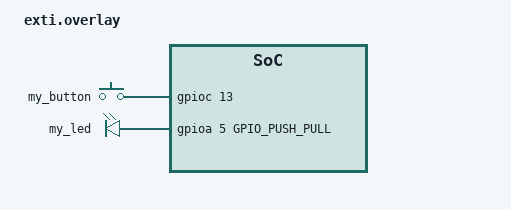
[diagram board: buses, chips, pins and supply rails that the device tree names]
#include <zephyr/dt-bindings/gpio/gpio.h>

/ {
    buttons {
        compatible = "gpio-keys";
        my_button: button_0 {
            gpios = <&gpioc 13 (GPIO_PULL_DOWN | GPIO_ACTIVE_HIGH)>;
        };
    };

    leds{
        compatible = "gpio-leds";
        my_led: led_0
        {
            gpios = <&gpioa 5 GPIO_PUSH_PULL>;
        };
    };
    
    aliases {
        sw0 = &my_button;
        led0 = &my_led;
    };
};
